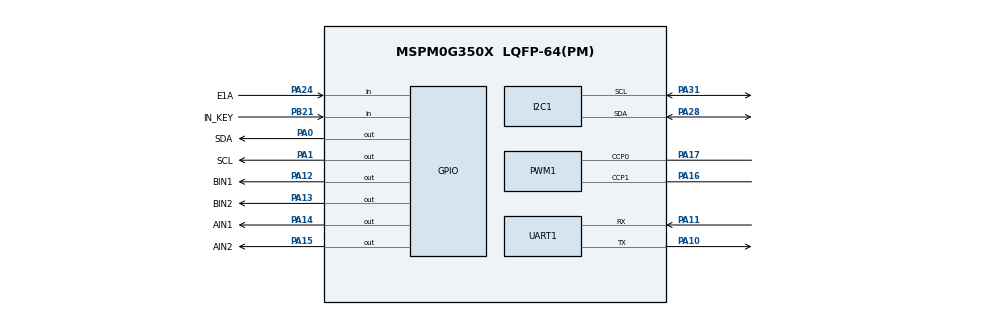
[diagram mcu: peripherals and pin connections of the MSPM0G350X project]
/**
 * @cliArgs --device "MSPM0G350X" --part "Default" --package "LQFP-64(PM)" --product "mspm0_sdk@2.10.00.04"
 * @versions {"tool":"1.26.2+4477"}
 */

/**
 * Import the modules used in this configuration.
 */
const ADC12   = scripting.addModule("/ti/driverlib/ADC12", {}, false);
const ADC121  = ADC12.addInstance();
const GPIO    = scripting.addModule("/ti/driverlib/GPIO", {}, false);
const GPIO1   = GPIO.addInstance();
const GPIO2   = GPIO.addInstance();
const GPIO3   = GPIO.addInstance();
const GPIO4   = GPIO.addInstance();
const GPIO5   = GPIO.addInstance();
const GPIO6   = GPIO.addInstance();
const I2C     = scripting.addModule("/ti/driverlib/I2C", {}, false);
const I2C1    = I2C.addInstance();
const PWM     = scripting.addModule("/ti/driverlib/PWM", {}, false);
const PWM1    = PWM.addInstance();
const SYSCTL  = scripting.addModule("/ti/driverlib/SYSCTL");
const SYSTICK = scripting.addModule("/ti/driverlib/SYSTICK");
const TIMER   = scripting.addModule("/ti/driverlib/TIMER", {}, false);
const TIMER1  = TIMER.addInstance();
const TIMER2  = TIMER.addInstance();
const UART    = scripting.addModule("/ti/driverlib/UART", {}, false);
const UART1   = UART.addInstance();

/**
 * Write custom configuration values to the imported modules.
 */
const divider9       = system.clockTree["UDIV"];
divider9.divideValue = 2;

const mux4       = system.clockTree["EXHFMUX"];
mux4.inputSelect = "EXHFMUX_XTAL";

const mux8       = system.clockTree["HSCLKMUX"];
mux8.inputSelect = "HSCLKMUX_SYSPLL2X";

const mux12       = system.clockTree["SYSPLLMUX"];
mux12.inputSelect = "zSYSPLLMUX_HFCLK";

const pinFunction4        = system.clockTree["HFXT"];
pinFunction4.inputFreq    = 40;
pinFunction4.enable       = true;
pinFunction4.HFCLKMonitor = true;
pinFunction4.HFXTStartup  = 20;

ADC121.$name                             = "ADC_VOLTAGE";
ADC121.sampClkSrc                        = "DL_ADC12_CLOCK_ULPCLK";
ADC121.sampClkDiv                        = "DL_ADC12_CLOCK_DIVIDE_8";
ADC121.repeatMode                        = true;
ADC121.sampleTime0                       = "2us";
ADC121.configureDMA                      = true;
ADC121.sampCnt                           = 1;
ADC121.enabledDMATriggers                = ["DL_ADC12_DMA_MEM0_RESULT_LOADED"];
ADC121.peripheral.$assign                = "ADC0";
ADC121.peripheral.adcPin0.$assign        = "PA27";
ADC121.adcPin0Config.$name               = "ti_driverlib_gpio_GPIOPinGeneric6";
ADC121.adcPin0Config.hideOutputInversion = scripting.forceWrite(false);
ADC121.DMA_CHANNEL.$name                 = "DMA_CH0";
ADC121.DMA_CHANNEL.addressMode           = "f2b";
ADC121.DMA_CHANNEL.srcLength             = "HALF_WORD";
ADC121.DMA_CHANNEL.dstLength             = "HALF_WORD";
ADC121.DMA_CHANNEL.configureTransferSize = true;
ADC121.DMA_CHANNEL.transferSize          = 40;
ADC121.DMA_CHANNEL.transferMode          = "FULL_CH_REPEAT_SINGLE";

const Board = scripting.addModule("/ti/driverlib/Board", {}, false);

GPIO1.$name                         = "LED";
GPIO1.associatedPins[0].ioStructure = "SD";
GPIO1.associatedPins[0].assignedPin = "22";
GPIO1.associatedPins[0].$name       = "KEY";

GPIO2.$name                          = "IIC_Software";
GPIO2.associatedPins.create(2);
GPIO2.associatedPins[0].$name        = "SCL";
GPIO2.associatedPins[0].initialValue = "SET";
GPIO2.associatedPins[0].ioStructure  = "OD";
GPIO2.associatedPins[0].assignedPin  = "1";
GPIO2.associatedPins[0].assignedPort = "PORTA";
GPIO2.associatedPins[0].pin.$assign  = "PA1";
GPIO2.associatedPins[1].$name        = "SDA";
GPIO2.associatedPins[1].initialValue = "SET";
GPIO2.associatedPins[1].ioStructure  = "OD";
GPIO2.associatedPins[1].assignedPort = "PORTA";
GPIO2.associatedPins[1].assignedPin  = "0";
GPIO2.associatedPins[1].pin.$assign  = "PA0";

GPIO3.$name                          = "Motor";
GPIO3.port                           = "PORTA";
GPIO3.associatedPins.create(4);
GPIO3.associatedPins[0].$name        = "AIN1";
GPIO3.associatedPins[0].initialValue = "SET";
GPIO3.associatedPins[0].assignedPin  = "14";
GPIO3.associatedPins[0].pin.$assign  = "PA14";
GPIO3.associatedPins[1].$name        = "AIN2";
GPIO3.associatedPins[1].initialValue = "SET";
GPIO3.associatedPins[1].assignedPin  = "15";
GPIO3.associatedPins[1].pin.$assign  = "PA15";
GPIO3.associatedPins[2].$name        = "BIN1";
GPIO3.associatedPins[2].initialValue = "SET";
GPIO3.associatedPins[2].assignedPin  = "12";
GPIO3.associatedPins[2].pin.$assign  = "PA12";
GPIO3.associatedPins[3].$name        = "BIN2";
GPIO3.associatedPins[3].initialValue = "SET";
GPIO3.associatedPins[3].assignedPin  = "13";
GPIO3.associatedPins[3].pin.$assign  = "PA13";

GPIO4.port                          = "PORTB";
GPIO4.$name                         = "Gray_Address";
GPIO4.associatedPins.create(3);
GPIO4.associatedPins[0].$name       = "P0";
GPIO4.associatedPins[0].assignedPin = "6";
GPIO4.associatedPins[1].$name       = "P1";
GPIO4.associatedPins[1].assignedPin = "7";
GPIO4.associatedPins[2].$name       = "P2";
GPIO4.associatedPins[2].assignedPin = "23";

GPIO5.$name                               = "Encoder";
GPIO5.port                                = "PORTA";
GPIO5.associatedPins.create(4);
GPIO5.associatedPins[0].$name             = "E1A";
GPIO5.associatedPins[0].direction         = "INPUT";
GPIO5.associatedPins[0].interruptEn       = true;
GPIO5.associatedPins[0].assignedPin       = "24";
GPIO5.associatedPins[0].interruptPriority = "0";
GPIO5.associatedPins[0].polarity          = "RISE";
GPIO5.associatedPins[0].pin.$assign       = "PA24";
GPIO5.associatedPins[1].$name             = "E1B";
GPIO5.associatedPins[1].direction         = "INPUT";
GPIO5.associatedPins[1].assignedPin       = "25";
GPIO5.associatedPins[1].interruptEn       = true;
GPIO5.associatedPins[1].interruptPriority = "0";
GPIO5.associatedPins[1].polarity          = "RISE";
GPIO5.associatedPins[2].$name             = "E2A";
GPIO5.associatedPins[2].direction         = "INPUT";
GPIO5.associatedPins[2].assignedPin       = "26";
GPIO5.associatedPins[2].interruptEn       = true;
GPIO5.associatedPins[2].interruptPriority = "0";
GPIO5.associatedPins[2].polarity          = "RISE";
GPIO5.associatedPins[3].$name             = "E2B";
GPIO5.associatedPins[3].direction         = "INPUT";
GPIO5.associatedPins[3].interruptEn       = true;
GPIO5.associatedPins[3].interruptPriority = "0";
GPIO5.associatedPins[3].polarity          = "RISE";
GPIO5.associatedPins[3].assignedPin       = "22";

GPIO6.$name                              = "GRAY_IN";
GPIO6.associatedPins[0].$name            = "IN_KEY";
GPIO6.associatedPins[0].direction        = "INPUT";
GPIO6.associatedPins[0].internalResistor = "PULL_UP";
GPIO6.associatedPins[0].interruptEn      = true;
GPIO6.associatedPins[0].polarity         = "FALL";
GPIO6.associatedPins[0].pin.$assign      = "PB21";

I2C1.$name                             = "I2C_OLED";
I2C1.basicClockSourceDivider           = 4;
I2C1.basicEnableController             = true;
I2C1.basicControllerStandardBusSpeed   = "Fast";
I2C1.basicControllerBusSpeed           = 500000;
I2C1.peripheral.$assign                = "I2C0";
I2C1.peripheral.sdaPin.$assign         = "PA28";
I2C1.peripheral.sclPin.$assign         = "PA31";
I2C1.sdaPinConfig.hideOutputInversion  = scripting.forceWrite(false);
I2C1.sdaPinConfig.onlyInternalResistor = scripting.forceWrite(false);
I2C1.sdaPinConfig.passedPeripheralType = scripting.forceWrite("Digital");
I2C1.sdaPinConfig.$name                = "ti_driverlib_gpio_GPIOPinGeneric2";
I2C1.sclPinConfig.hideOutputInversion  = scripting.forceWrite(false);
I2C1.sclPinConfig.onlyInternalResistor = scripting.forceWrite(false);
I2C1.sclPinConfig.passedPeripheralType = scripting.forceWrite("Digital");
I2C1.sclPinConfig.$name                = "ti_driverlib_gpio_GPIOPinGeneric3";

PWM1.$name                      = "PWM_0";
PWM1.clockDivider               = 8;
PWM1.timerStartTimer            = true;
PWM1.peripheral.$assign         = "TIMA1";
PWM1.peripheral.ccp0Pin.$assign = "PA17";
PWM1.peripheral.ccp1Pin.$assign = "PA16";
PWM1.PWM_CHANNEL_0.$name        = "ti_driverlib_pwm_PWMTimerCC0";
PWM1.PWM_CHANNEL_0.invert       = true;
PWM1.PWM_CHANNEL_1.$name        = "ti_driverlib_pwm_PWMTimerCC1";
PWM1.PWM_CHANNEL_1.invert       = true;
PWM1.ccp0PinConfig.$name        = "ti_driverlib_gpio_GPIOPinGeneric4";
PWM1.ccp1PinConfig.$name        = "ti_driverlib_gpio_GPIOPinGeneric5";

SYSCTL.forceDefaultClkConfig = true;
SYSCTL.clockTreeEn           = true;
SYSCTL.validateClkStatus     = true;

SYSTICK.periodEnable    = true;
SYSTICK.interruptEnable = true;
SYSTICK.systickEnable   = true;
SYSTICK.period          = 80000;

TIMER1.$name              = "TIMER_0";
TIMER1.timerStartTimer    = true;
TIMER1.timerClkDiv        = 2;
TIMER1.timerClkPrescale   = 100;
TIMER1.timerPeriod        = "1ms";
TIMER1.timerMode          = "PERIODIC";
TIMER1.interrupts         = ["ZERO"];
TIMER1.peripheral.$assign = "TIMG0";

TIMER2.$name              = "TIMER_1";
TIMER2.timerClkDiv        = 8;
TIMER2.timerPeriod        = "5ms";
TIMER2.timerStartTimer    = true;
TIMER2.interrupts         = ["ZERO"];
TIMER2.interruptPriority  = "2";
TIMER2.timerMode          = "PERIODIC";
TIMER2.peripheral.$assign = "TIMG6";

UART1.$name                        = "UART_0";
UART1.targetBaudRate               = 115200;
UART1.peripheral.$assign           = "UART0";
UART1.peripheral.rxPin.$assign     = "PA11";
UART1.peripheral.txPin.$assign     = "PA10";
UART1.txPinConfig.$name            = "ti_driverlib_gpio_GPIOPinGeneric0";
UART1.txPinConfig.enableConfig     = true;
UART1.txPinConfig.internalResistor = "PULL_UP";
UART1.rxPinConfig.$name            = "ti_driverlib_gpio_GPIOPinGeneric1";
UART1.rxPinConfig.enableConfig     = true;
UART1.rxPinConfig.internalResistor = "PULL_UP";

/**
 * Pinmux solution for unlocked pins/peripherals. This ensures that minor changes to the automatic solver in a future
 * version of the tool will not impact the pinmux you originally saw.  These lines can be completely deleted in order to
 * re-solve from scratch.
 */
pinFunction4.peripheral.$suggestSolution           = "SYSCTL";
pinFunction4.peripheral.hfxInPin.$suggestSolution  = "PA5";
pinFunction4.peripheral.hfxOutPin.$suggestSolution = "PA6";
ADC121.DMA_CHANNEL.peripheral.$suggestSolution     = "DMA_CH0";
Board.peripheral.$suggestSolution                  = "DEBUGSS";
Board.peripheral.swclkPin.$suggestSolution         = "PA20";
Board.peripheral.swdioPin.$suggestSolution         = "PA19";
GPIO1.associatedPins[0].pin.$suggestSolution       = "PB22";
GPIO4.associatedPins[0].pin.$suggestSolution       = "PB6";
GPIO4.associatedPins[1].pin.$suggestSolution       = "PB7";
GPIO4.associatedPins[2].pin.$suggestSolution       = "PB23";
GPIO5.associatedPins[1].pin.$suggestSolution       = "PA25";
GPIO5.associatedPins[2].pin.$suggestSolution       = "PA26";
GPIO5.associatedPins[3].pin.$suggestSolution       = "PA22";
